# C2000_SCI_Type0_Registers register map
Vendor: Texas Instruments
Peripheral module from a debugger description file (folder C2000).
Address unit: 16 bits
Registers are 16-bit, read-write, no defined reset value unless marked. A register's access mark holds for its fields unless they carry their own. Offsets are as the file gives them; lines under a group give offsets from that group; [hi:lo] are bit positions; {n}, {i} and the like mark numbered series; 'fields as' and 'values as' point back to an identical list; <NAME> marks a mode.

## SCI_REGS — SCI Registers
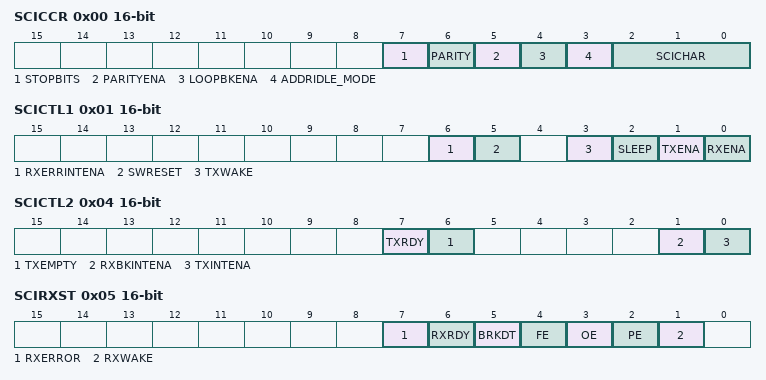
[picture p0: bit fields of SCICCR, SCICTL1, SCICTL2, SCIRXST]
0x00 SCICCR — Communications control register
  [7] STOPBITS — Number of Stop Bits
    0=One stop bit; 1=Two stop bits
  [6] PARITY — Even or Odd Parity
    0=Odd parity; 1=Even parity
  [5] PARITYENA — Parity enable
    0=Parity disabled; no parity bit is generated during transmission; 1=Parity is enabled
  [4] LOOPBKENA — Loop Back enable
    0=Loop Back test mode disabled; 1=Loop Back test mode enabled
  [3] ADDRIDLE_MODE — ADDR/IDLE Mode control
    0=Idle-line mode protocol selected; 1=Address-bit mode protocol selected
  [2:0] SCICHAR — Character length control
    0=SCICHAR_LEGNTH_1; 1=SCICHAR_LEGNTH_2; {v}=__{v} (SCICHAR_LEGNTH_{v+1}) (v=2..7)
0x01 SCICTL1 — Control register 1
  [6] RXERRINTENA — Recieve __interrupt enable
    0=Receive error interrupt disabled; 1=Receive error interrupt enabled
  [5] SWRESET — Software reset
    0=Writing a 0 to this bit initializes the SCI state machines and; 1=After a system reset, re-enable the SCI by writing a 1 to this
  [3] TXWAKE — Transmitter wakeup method
    0=Transmit feature is not selected; 1=Transmit feature selected is dependent on the mode, idle-line o
  [2] SLEEP — SCI sleep
    0=Sleep mode disabled; 1=Sleep mode enabled
  [1] TXENA — SCI transmitter enable
    0=Transmitter disabled; 1=Transmitter enabled
  [0] RXENA — SCI receiver enable
    0=Prevent received characters from transfer into the SCIRXEMU and; 1=Send received characters to SCIRXEMU and SCIRXBUF
0x02 SCIHBAUD — Baud rate (high) register
  [15:0] BAUD — SCI 16-bit baud selection Registers SCIHBAUD
0x03 SCILBAUD — Baud rate (low) register
  [15:0] BAUD — SCI 16-bit baud selection Registers SCILBAUD
0x04 SCICTL2 — Control register 2
  [7] TXRDY — Transmitter ready flag
    0=SCITXBUF is full; 1=SCITXBUF is ready to receive the next character
  [6] TXEMPTY — Transmitter empty flag
    0=Transmitter buffer or shift register or both are loaded with da; 1=Transmitter buffer and shift registers are both empty
  [1] RXBKINTENA — Receiver-buffer break enable
    0=Disable RXRDY/BRKDT interrupt; 1=Enable RXRDY/BRKDT interrupt
  [0] TXINTENA — Transmit __interrupt enable
    0=Disable TXRDY interrupt; 1=Enable TXRDY interrupt
0x05 SCIRXST — Recieve status register
  [7] RXERROR — Receiver error flag
    0=No error flags set; 1=Error flag(s) set
  [6] RXRDY — Receiver ready flag
    0=No new character in SCIRXBUF; 1=Character ready to be read from SCIRXBUF
  [5] BRKDT — Break-detect flag
    0=No break condition; 1=Break condition occurred
  [4] FE — Framing error flag
    0=No framing error detected; 1=Framing error detected
  [3] OE — Overrun error flag
    0=No overrun error detected; 1=Overrun error detected
  [2] PE — Parity error flag
    0=No parity error or parity is disabled; 1=Parity error is detected
  [1] RXWAKE — Receiver wakeup detect flag
    0=No detection of a receiver wake-up condition; 1=A value of 1 in this bit indicates detection of a receiver wake
0x06 SCIRXEMU — Recieve emulation buffer register
  [7:0] ERXDT — Receive emulation buffer data
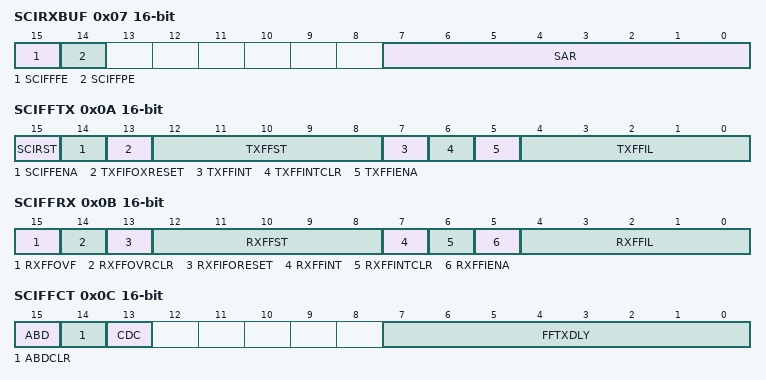
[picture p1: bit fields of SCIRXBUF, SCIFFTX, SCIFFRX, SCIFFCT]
0x07 SCIRXBUF — Recieve data buffer
  [15] SCIFFFE — Receiver error flag
    0=No parity error occurred while receiving the character, in bits; 1=A parity error occurred while receiving the character in bits 7
  [14] SCIFFPE — Receiver error flag
    0=No frame error occurred while receiving the character, in bits; 1=A frame error occurred while receiving the character in bits 7-
  [7:0] SAR — Receive Character bits
0x09 SCITXBUF — Transmit data buffer
  [7:0] TXDT
0x0A SCIFFTX — FIFO transmit register
  [15] SCIRST — SCI reset rx/tx channels
  [14] SCIFFENA — Enhancement enable
    0=SCI FIFO enhancements are disabled; 1=SCI FIFO enhancements are enabled
  [13] TXFIFOXRESET — FIFO reset
    0=Reset the FIFO pointer to zero and hold in reset; 1=Re-enable transmit FIFO operation
  [12:8] TXFFST — FIFO status
    0=Transmit FIFO is empty; 1=Transmit FIFO has 1 words; 2=__2 (Transmit FIFO has 2 words); 3=__3 (Transmit FIFO has 3 words); 4=__4 (Transmit FIFO has 4 words)
  [7] TXFFINT — INT flag
    0=TXFIFO interrupt has not occurred, read-only bit; 1=TXFIFO interrupt has occurred, read-only bit
  [6] TXFFINTCLR — Clear INT flag
    0=Write 0 has no effect on TXFIFINT flag bit, Bit reads back a ze; 1=Write 1 to clear TXFFINT flag in bit 7
  [5] TXFFIENA — Interrupt enable
    0=TX FIFO interrupt based on TXFFIVL match (less than or equal to; 1=TX FIFO interrupt based on TXFFIVL match (less than or equal to
  [4:0] TXFFIL — Interrupt level
0x0B SCIFFRX — FIFO recieve register
  [15] RXFFOVF — FIFO overflow
    0=Receive FIFO has not overflowed, read-only bit; 1=Receive FIFO has overflowed, read-only bit
  [14] RXFFOVRCLR — Clear overflow
    0=Write 0 has no effect on RXFFOVF flag bit, Bit reads back a zero; 1=Write 1 to clear RXFFOVF flag in bit 15
  [13] RXFIFORESET — FIFO reset
    0=Write 0 to reset the FIFO pointer to zero, and hold in reset; 1=Re-enable receive FIFO operation
  [12:8] RXFFST — FIFO status
    0=Receive FIFO is empty; 1=Receive FIFO has 1 words; 2=__2 (Receive FIFO has 2 words); 3=__3 (Receive FIFO has 3 words); 4=__4 (Receive FIFO has 4 words)
  [7] RXFFINT — INT flag
    0=RXFIFO interrupt has not occurred, read-only bit; 1=RXFIFO interrupt has occurred, read-only bit
  [6] RXFFINTCLR — Clear INT flag
    0=Write 0 has no effect on RXFIFINT flag bit; 1=Write 1 to clear RXFFINT flag in bit 7
  [5] RXFFIENA — Interrupt enable
    0=RX FIFO interrupt based on RXFFIVL match (less than or equal to; 1=RX FIFO interrupt based on RXFFIVL match (less than or equal to
  [4:0] RXFFIL — Interrupt level
0x0C SCIFFCT — FIFO control register
  [15] ABD — Auto baud detect
    0=Auto-baud detection is not complete; 1=Auto-baud hardware has detected "A" or "a" character on the SCI
  [14] ABDCLR — Auto baud clear
    0=Write 0 has no effect on ABD flag bit. Bit reads back a zero.; 1=Write 1 to clear ABD flag in bit 15
  [13] CDC — Auto baud mode enable
    0=Disables auto-baud alignment; 1=Enables auto-baud alignment
  [7:0] FFTXDLY — FIFO transmit delay
0x0F SCIPRI — FIFO Priority control
  [4:3] FREESOFT — Emulation modes
    0=Immediate stop on suspend; 1=Complete current receive/transmit sequence before stopping; 2=__2 (Free run); 3=__3 (Free run)
